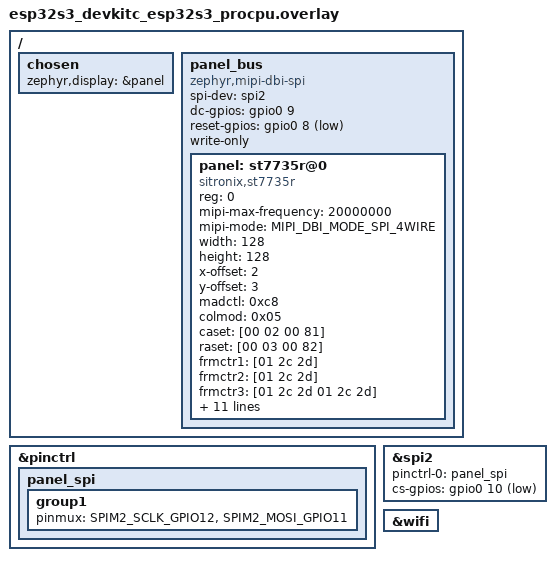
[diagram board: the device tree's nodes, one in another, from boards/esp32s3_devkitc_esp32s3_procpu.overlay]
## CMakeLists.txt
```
cmake_minimum_required(VERSION 3.20.0)
find_package(Zephyr REQUIRED HINTS $ENV{ZEPHYR_BASE})
project(lvgl_esp32s3)
target_include_directories(app PRIVATE include ui "${ZEPHYR_BASE}/../modules/lib/cjson")
target_sources(app PRIVATE src/main.c src/sensor_model.c src/sensor_json.c
  src/response_buffer.c ui/ui.c "${ZEPHYR_BASE}/../modules/lib/cjson/cJSON.c")
if(CONFIG_APP_NETWORK)
  target_sources(app PRIVATE src/config_store.c src/wifi_manager.c src/api_client.c src/provisioning.c)
  # Only a public CA certificate is embedded. Runtime credentials stay in NVS.
  if(APP_CA_CERT_FILE)
    file(READ "${APP_CA_CERT_FILE}" ca_hex HEX)
    string(REGEX REPLACE "(..)" "0x\\1," ca_bytes "${ca_hex}")
    file(WRITE "${PROJECT_BINARY_DIR}/api_ca.inc" "${ca_bytes}0x00")
  else()
    file(WRITE "${PROJECT_BINARY_DIR}/api_ca.inc" "0x00")
  endif()
  target_include_directories(app PRIVATE "${PROJECT_BINARY_DIR}")
endif()

target_compile_definitions(app PRIVATE CJSON_NESTING_LIMIT=16)
```

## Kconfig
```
mainmenu "128x128 Zephyr sensor display"
source "Kconfig.zephyr"
menu "Sensor application"
config APP_NETWORK
    bool "Wi-Fi, settings and HTTPS polling"
    default n
config APP_WIFI_RETRY_SECONDS
    int "Wi-Fi retry interval"
    range 1 300
    default 10
config APP_POLL_SECONDS
    int "HTTPS polling interval"
    range 1 3600
    default 10
endmenu
```

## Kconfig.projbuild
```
menu "Example Configuration"

    config ESP_WIFI_SSID
        string "WiFi SSID"
        default "İD"
        help
            SSID (network name) for the example to connect to.

    config ESP_WIFI_PASSWORD
        string "WiFi Password"
        default "Pasword*"
        help
            WiFi password (WPA or WPA2) for the example to use.

    config ESP_MAXIMUM_RETRY
        int "Maximum retry"
        default 5
        help
            Set the Maximum retry to avoid station reconnecting to the AP unlimited when the AP is really inexistent.

    choice ESP_WIFI_SCAN_AUTH_MODE_THRESHOLD
        prompt "WiFi Scan auth mode threshold"
        default ESP_WIFI_AUTH_WPA2_PSK
        help
            The weakest authmode to accept in the scan mode.
            This value defaults to ESP_WIFI_AUTH_WPA2_PSK incase password is present and ESP_WIFI_AUTH_OPEN is used.
            Please select ESP_WIFI_AUTH_WEP/ESP_WIFI_AUTH_WPA_PSK incase AP is operating in WEP/WPA mode.

        config ESP_WIFI_AUTH_OPEN
            bool "OPEN"
        config ESP_WIFI_AUTH_WEP
            bool "WEP"
        config ESP_WIFI_AUTH_WPA_PSK
            bool "WPA PSK"
        config ESP_WIFI_AUTH_WPA2_PSK
            bool "WPA2 PSK"
        config ESP_WIFI_AUTH_WPA_WPA2_PSK
            bool "WPA/WPA2 PSK"
        config ESP_WIFI_AUTH_WPA3_PSK
            bool "WPA3 PSK"
        config ESP_WIFI_AUTH_WPA2_WPA3_PSK
            bool "WPA2/WPA3 PSK"
        config ESP_WIFI_AUTH_WAPI_PSK
            bool "WAPI PSK"
    endchoice

endmenu
```

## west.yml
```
manifest:
  version: "0.13"
  projects:
    - name: zephyr
      url: https://github.com/zephyrproject-rtos/zephyr
      revision: v4.1.0
      import:
        name-allowlist: [cmsis, hal_espressif, mbedtls, lvgl]
    - name: cjson
      url: https://github.com/DaveGamble/cJSON
      revision: v1.7.18
      path: modules/lib/cjson
  self:
    path: LVGL-ESP32S3
```

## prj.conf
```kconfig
CONFIG_DISPLAY=y
CONFIG_LVGL=y
CONFIG_LV_COLOR_DEPTH_16=y
CONFIG_LV_USE_LABEL=y
CONFIG_LV_USE_BUTTON=y
CONFIG_LV_FONT_MONTSERRAT_14=y
CONFIG_LV_FONT_MONTSERRAT_24=y
CONFIG_LV_Z_MEM_POOL_SIZE=16384
CONFIG_MAIN_STACK_SIZE=4096
CONFIG_HEAP_MEM_POOL_SIZE=16384
CONFIG_LOG=y
CONFIG_LOG_DEFAULT_LEVEL=3
```

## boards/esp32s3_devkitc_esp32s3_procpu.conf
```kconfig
CONFIG_APP_NETWORK=y
CONFIG_SPI=y
CONFIG_GPIO=y
CONFIG_WIFI=y
CONFIG_WIFI_ESP32=y
CONFIG_NET_L2_ETHERNET=y
CONFIG_NETWORKING=y
CONFIG_NET_IPV4=y
CONFIG_NET_IPV6=n
CONFIG_NET_DHCPV4=y
CONFIG_NET_TCP=y
CONFIG_NET_UDP=y
CONFIG_NET_SOCKETS=y
CONFIG_NET_MGMT=y
CONFIG_NET_MGMT_EVENT=y
CONFIG_NET_MGMT_EVENT_INFO=y
CONFIG_DNS_RESOLVER=y
CONFIG_HTTP_CLIENT=y
CONFIG_SNTP=y
CONFIG_POSIX_TIMERS=y
CONFIG_NET_SOCKETS_SOCKOPT_TLS=y
CONFIG_TLS_CREDENTIALS=y
CONFIG_MBEDTLS=y
CONFIG_MBEDTLS_ENABLE_HEAP=y
CONFIG_MBEDTLS_HEAP_SIZE=49152
CONFIG_MBEDTLS_PEM_CERTIFICATE_FORMAT=y
CONFIG_MBEDTLS_SSL_MAX_CONTENT_LEN=4096
CONFIG_NEWLIB_LIBC=y
CONFIG_FLASH=y
CONFIG_FLASH_MAP=y
CONFIG_FLASH_PAGE_LAYOUT=y
CONFIG_NVS=y
CONFIG_SETTINGS=y
CONFIG_SETTINGS_NVS=y
CONFIG_SHELL=y
CONFIG_SHELL_STACK_SIZE=4096
CONFIG_SHELL_CMD_BUFF_SIZE=1536
CONFIG_REBOOT=y
CONFIG_HEAP_MEM_POOL_SIZE=49152
CONFIG_NET_PKT_RX_COUNT=16
CONFIG_NET_PKT_TX_COUNT=16
CONFIG_NET_BUF_RX_COUNT=32
CONFIG_NET_BUF_TX_COUNT=32
```

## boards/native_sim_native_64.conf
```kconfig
CONFIG_SDL_DISPLAY=y
CONFIG_INPUT=y
CONFIG_LV_Z_POINTER_INPUT=y
```

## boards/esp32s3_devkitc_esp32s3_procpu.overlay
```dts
/* Reference wiring only: ESP32-S3-DevKitC + 128x128 ST7735R.
 * Confirm the controller and wiring on your module before using this overlay.
 * SPI: SCK=12 MOSI=11 CS=10 DC=9 RESET=8. Backlight: external 3.3 V.
 */
#include <zephyr/dt-bindings/gpio/gpio.h>
#include <zephyr/dt-bindings/pinctrl/esp32s3-pinctrl.h>
/ {
    chosen {
        zephyr,display = &panel;
    };
    panel_bus {
        compatible = "zephyr,mipi-dbi-spi";
        spi-dev = <&spi2>;
        dc-gpios = <&gpio0 9 GPIO_ACTIVE_HIGH>;
        reset-gpios = <&gpio0 8 GPIO_ACTIVE_LOW>;
        write-only;
        #address-cells = <1>;
        #size-cells = <0>;
    panel: st7735r@0 {
        compatible = "sitronix,st7735r";
        reg = <0>;
        mipi-max-frequency = <20000000>;
        mipi-mode = "MIPI_DBI_MODE_SPI_4WIRE";
        width = <128>;
        height = <128>;
        x-offset = <2>;
        y-offset = <3>;
        madctl = <0xc8>;
        colmod = <0x05>;
        caset = [00 02 00 81];
        raset = [00 03 00 82];
        frmctr1 = [01 2c 2d];
        frmctr2 = [01 2c 2d];
        frmctr3 = [01 2c 2d 01 2c 2d];
        invctr = <0x07>;
        pwctr1 = [a2 02 84];
        pwctr2 = [c5];
        pwctr3 = [0a 00];
        pwctr4 = [8a 2a];
        pwctr5 = [8a ee];
        vmctr1 = <0x0e>;
        gamctrp1 = [02 1c 07 12 37 32 29 2d 29 25 2b 39 00 01 03 10];
        gamctrn1 = [03 1d 07 06 2e 2c 29 2d 2e 2e 37 3f 00 00 02 10];
    };
    };
};
&pinctrl {
    panel_spi: panel_spi {
        group1 {
            pinmux = <SPIM2_SCLK_GPIO12>, <SPIM2_MOSI_GPIO11>;
        };
    };
};
&spi2 {
    status = "okay";
    pinctrl-0 = <&panel_spi>;
    pinctrl-names = "default";
    cs-gpios = <&gpio0 10 GPIO_ACTIVE_LOW>;
};
&wifi {
    status = "okay";
};
```

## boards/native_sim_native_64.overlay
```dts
&sdl_dc {
    width = <128>;
    height = <128>;
};
```

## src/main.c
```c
#include "ui.h"
#include "sensor_model.h"
#include <zephyr/device.h>
#include <zephyr/drivers/display.h>
#include <zephyr/kernel.h>
#include <zephyr/logging/log.h>
#ifdef CONFIG_APP_NETWORK
#include "config_store.h"
#include "wifi_manager.h"
#include "api_client.h"
#endif
LOG_MODULE_REGISTER(panel_app);
int main(void)
{
    const struct device *display = DEVICE_DT_GET(DT_CHOSEN(zephyr_display));
    if (!device_is_ready(display)) {
        LOG_ERR("Display device is not ready");
        return 0;
    }
    struct display_capabilities caps;
    display_get_capabilities(display, &caps);
    if (caps.x_resolution != 128 || caps.y_resolution != 128) {
        LOG_ERR("This UI requires a 128x128 display");
        return 0;
    }
    ui_init();
    lv_timer_handler();
    display_blanking_off(display);
#ifdef CONFIG_APP_NETWORK
    static struct app_config config;
    int err = config_store_init();
    if (!err) {
        config_store_get(&config);
        if (config.ssid[0]) {
            err = wifi_manager_init(config.ssid, config.password);
            if (!err && config.api_host[0]) {
                err = api_client_start(&config);
            }
        } else {
            LOG_INF("Provision with 'panel set', then reboot");
        }
    }
    if (err) {
        sensor_model_error(err);
        LOG_ERR("Network initialization failed: %d", err);
    }
#endif
    /* Only this thread calls LVGL. Workers publish plain data under a mutex. */
    for (;;) {
        struct sensor_state state;
        sensor_model_get(&state);
        bool online = false;
#ifdef CONFIG_APP_NETWORK
        online = wifi_manager_is_connected();
#endif
        ui_render(&state, online);
        lv_timer_handler();
        k_sleep(K_MSEC(20));
    }
}
```

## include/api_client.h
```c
#ifndef API_CLIENT_H
#define API_CLIENT_H
#include "config_store.h"
int api_client_start(const struct app_config *config);
#endif
```

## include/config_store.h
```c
#ifndef PANEL_CONFIG_STORE_H
#define PANEL_CONFIG_STORE_H
struct app_config {
    char ssid[33];
    char password[65];
    char api_host[128];
    char api_path[192];
    char api_body[1024];
    char ntp_host[128];
};
int config_store_init(void);
void config_store_get(struct app_config *out);
int config_store_set(const char *key, const char *value);
#endif
```

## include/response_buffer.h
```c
#ifndef RESPONSE_BUFFER_H
#define RESPONSE_BUFFER_H
#include <stddef.h>
struct response_buffer {
    char data[4096];
    size_t used;
    int error;
};
int response_buffer_append(struct response_buffer *buffer, const char *data, size_t length);
#endif
```

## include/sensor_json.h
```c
#ifndef SENSOR_JSON_H
#define SENSOR_JSON_H
#include <stddef.h>
#include <stdint.h>
/* Length excludes the terminating NUL; input must have length + 1 bytes. */
int sensor_json_parse(const char *json, size_t length, int32_t *centi_value);
#endif
```

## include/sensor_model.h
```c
#ifndef SENSOR_MODEL_H
#define SENSOR_MODEL_H
#include <stdbool.h>
#include <stdint.h>
#include <zephyr/kernel.h>
struct sensor_state {
    bool valid;
    int32_t centi_value;
    int64_t updated_ms;
    int error;
};
void sensor_model_update(int32_t value);
void sensor_model_error(int error);
void sensor_model_get(struct sensor_state *out);
void sensor_request_refresh(void);
int sensor_wait_refresh(k_timeout_t timeout);
#endif
```

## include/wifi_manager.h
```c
#ifndef WIFI_MANAGER_H
#define WIFI_MANAGER_H
#include <stdbool.h>
#include <zephyr/kernel.h>

typedef enum {
    WIFI_MANAGER_DISCONNECTED,
    WIFI_MANAGER_CONNECTING,
    WIFI_MANAGER_CONNECTED
} wifi_manager_state_t;
/* Initialize once from main after settings have loaded. */
int wifi_manager_init(const char *ssid, const char *password);
bool wifi_manager_is_connected(void);
wifi_manager_state_t wifi_manager_get_state(void);
/* Single MQTT consumer; always rechecks current state after waking. */
int wifi_manager_wait_ready(k_timeout_t timeout);
#endif
```

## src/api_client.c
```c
#include "api_client.h"
#include "wifi_manager.h"
#include "sensor_model.h"
#include "sensor_json.h"
#include "response_buffer.h"
#include <errno.h>
#include <string.h>
#include <time.h>
#include <zephyr/kernel.h>
#include <zephyr/logging/log.h>
#include <zephyr/net/http/client.h>
#include <zephyr/net/socket.h>
#include <zephyr/net/sntp.h>
#include <zephyr/net/tls_credentials.h>
#include <zephyr/posix/time.h>
LOG_MODULE_REGISTER(api_client);
static struct app_config config;
static const unsigned char ca_certificate[] = {
#include "api_ca.inc"
};
static const sec_tag_t ca_tag = 1;
static struct k_thread api_thread;
K_THREAD_STACK_DEFINE(panel_api_stack, 8192);
static uint8_t receive_buffer[1024];
static struct response_buffer response;
static bool complete;
static int http_status;

static void receive_response(struct http_response *rsp,
                             enum http_final_call final, void *user_data)
{
    ARG_UNUSED(user_data);
    http_status = rsp->http_status_code;
    response_buffer_append(&response, rsp->body_frag_start, rsp->body_frag_len);
    if (final == HTTP_DATA_FINAL) {
        complete = true;
    }
}

static int synchronize_time(void)
{
    struct sntp_time time;
    int err = sntp_simple(config.ntp_host, 10000, &time);
    if (err) {
        return err;
    }
    struct timespec now = { .tv_sec = time.seconds, .tv_nsec = 0 };
    return clock_settime(CLOCK_REALTIME, &now) ? -errno : 0;
}

static int request_sample(void)
{
    struct zsock_addrinfo *addresses = NULL;
    struct zsock_addrinfo hints = {
        .ai_family = AF_INET, .ai_socktype = SOCK_STREAM
    };
    if (zsock_getaddrinfo(config.api_host, "443", &hints, &addresses)) {
        return -EHOSTUNREACH;
    }
    int socket = zsock_socket(AF_INET, SOCK_STREAM, IPPROTO_TLS_1_2);
    int err = 0;
    if (socket < 0) {
        err = -errno;
        goto free_addresses;
    }
    int verify = TLS_PEER_VERIFY_REQUIRED;
    struct timeval timeout = { .tv_sec = 10 };
    if (zsock_setsockopt(socket, SOL_TLS, TLS_SEC_TAG_LIST, &ca_tag, sizeof(ca_tag)) ||
        zsock_setsockopt(socket, SOL_TLS, TLS_HOSTNAME, config.api_host,
                         strlen(config.api_host)) ||
        zsock_setsockopt(socket, SOL_TLS, TLS_PEER_VERIFY, &verify, sizeof(verify)) ||
        zsock_setsockopt(socket, SOL_SOCKET, SO_RCVTIMEO, &timeout, sizeof(timeout)) ||
        zsock_setsockopt(socket, SOL_SOCKET, SO_SNDTIMEO, &timeout, sizeof(timeout))) {
        err = -errno;
        goto close_socket;
    }
    if (!addresses || zsock_connect(socket, addresses->ai_addr, addresses->ai_addrlen)) {
        err = addresses ? -errno : -EHOSTUNREACH;
        goto close_socket;
    }
    response = (struct response_buffer){0};
    complete = false;
    http_status = 0;
    struct http_request request = {
        .method = HTTP_POST,
        .url = config.api_path,
        .host = config.api_host,
        .protocol = "HTTP/1.1",
        .content_type_value = "application/json",
        .payload = config.api_body,
        .payload_len = strlen(config.api_body),
        .response = receive_response,
        .recv_buf = receive_buffer,
        .recv_buf_len = sizeof(receive_buffer),
    };
    err = http_client_req(socket, &request, 10000, NULL);
    if (err >= 0) {
        err = response.error ? response.error :
              !complete ? -EBADMSG :
              http_status != 200 ? -EACCES : 0;
        if (!err) {
            int32_t value;
            err = sensor_json_parse(response.data, response.used, &value);
            if (!err) {
                sensor_model_update(value);
            }
        }
    }
close_socket:
    zsock_close(socket);
free_addresses:
    if (addresses) {
        zsock_freeaddrinfo(addresses);
    }
    return err;
}

static void poll_api(void *a, void *b, void *c)
{
    ARG_UNUSED(a); ARG_UNUSED(b); ARG_UNUSED(c);
    bool time_ready = false;
    for (;;) {
        if (wifi_manager_wait_ready(K_SECONDS(5))) {
            continue;
        }
        int err = 0;
        if (!time_ready) {
            err = synchronize_time();
            time_ready = !err;
        }
        if (!err) {
            err = request_sample();
        }
        if (err) {
            sensor_model_error(err);
            LOG_WRN("Sensor request failed: %d", err);
        }
        sensor_wait_refresh(K_SECONDS(CONFIG_APP_POLL_SECONDS));
    }
}

int api_client_start(const struct app_config *cfg)
{
    if (!cfg || !cfg->api_host[0] || cfg->api_path[0] != '/') {
        return -EINVAL;
    }
    /* No verification bypass: an absent CA keeps HTTPS disabled. */
    if (sizeof(ca_certificate) <= 1) {
        return -EACCES;
    }
    int err = tls_credential_add(ca_tag, TLS_CREDENTIAL_CA_CERTIFICATE,
                                 ca_certificate, sizeof(ca_certificate));
    if (err) {
        return err;
    }
    config = *cfg;
    k_thread_create(&api_thread, panel_api_stack, K_THREAD_STACK_SIZEOF(panel_api_stack),
                    poll_api, NULL, NULL, NULL, 7, 0, K_NO_WAIT);
    return 0;
}
```

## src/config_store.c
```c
#include "config_store.h"
#include <errno.h>
#include <string.h>
#include <stdio.h>
#include <zephyr/kernel.h>
#include <zephyr/settings/settings.h>
#include <zephyr/sys/util.h>

static struct app_config config = { .api_path = "/", .api_body = "{}", .ntp_host = "pool.ntp.org" };
K_MUTEX_DEFINE(config_lock);

static char *field(const char *key, size_t *size)
{
    if (!key) {
        return NULL;
    }
    if (!strcmp(key, "ssid")) {
        *size = sizeof(config.ssid);
        return config.ssid;
    }
    if (!strcmp(key, "password")) {
        *size = sizeof(config.password);
        return config.password;
    }
    if (!strcmp(key, "api_host")) {
        *size = sizeof(config.api_host);
        return config.api_host;
    }
    if (!strcmp(key, "api_path")) {
        *size = sizeof(config.api_path);
        return config.api_path;
    }
    if (!strcmp(key, "api_body")) {
        *size = sizeof(config.api_body);
        return config.api_body;
    }
    if (!strcmp(key, "ntp_host")) {
        *size = sizeof(config.ntp_host);
        return config.ntp_host;
    }
    return NULL;
}

static int load_setting(const char *key, size_t len,
                        settings_read_cb read_cb, void *cb_arg)
{
    char value[1024] = {0};
    size_t capacity;
    char *dst = field(key, &capacity);
    if (!dst) {
        return -ENOENT;
    }
    if (len >= capacity) {
        return -EINVAL;
    }
    ssize_t read = read_cb(cb_arg, value, len);
    if (read < 0) {
        return (int)read;
    }
    if ((size_t)read != len || memchr(value, '\0', len)) {
        return -EINVAL;
    }
    k_mutex_lock(&config_lock, K_FOREVER);
    memset(dst, 0, capacity);
    memcpy(dst, value, len);
    k_mutex_unlock(&config_lock);
    return 0;
}
SETTINGS_STATIC_HANDLER_DEFINE(iot, "iot", NULL, load_setting, NULL, NULL);

int config_store_init(void)
{
    int err = settings_subsys_init();
    return err ? err : settings_load_subtree("iot");
}

void config_store_get(struct app_config *out)
{
    k_mutex_lock(&config_lock, K_FOREVER);
    *out = config;
    k_mutex_unlock(&config_lock);
}

int config_store_set(const char *key, const char *value)
{
    size_t capacity;
    char path[48];
    char *dst = field(key, &capacity);
    if (!dst || !value) {
        return -EINVAL;
    }
    size_t len = strlen(value);
    if (len >= capacity || (!strcmp(key, "api_path") && (!len || value[0] != '/'))) {
        return -EINVAL;
    }
    if (!strcmp(key, "password") && len && (len < 8 || len > 63)) {
        return -EINVAL;
    }
    if ((!strcmp(key, "api_host") || !strcmp(key, "ntp_host")) &&
        strpbrk(value, "\r\n/ :")) {
        return -EINVAL;
    }
    if (!strcmp(key, "api_path") && strpbrk(value, "\r\n")) {
        return -EINVAL;
    }
    /* Serialize flash and RAM updates so concurrent writers cannot diverge. */
    k_mutex_lock(&config_lock, K_FOREVER);
    snprintf(path, sizeof(path), "iot/%s", key);
    int err = settings_save_one(path, value, len);
    if (!err) {
        memset(dst, 0, capacity);
        memcpy(dst, value, len);
    }
    k_mutex_unlock(&config_lock);
    return err;
}
```

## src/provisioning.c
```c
#include "config_store.h"
#include "sensor_model.h"
#include <zephyr/shell/shell.h>
#include <zephyr/sys/reboot.h>
static int set_config(const struct shell *sh, size_t argc, char **argv)
{
    ARG_UNUSED(argc);
    int err = config_store_set(argv[1], argv[2]);
    if (err) {
        shell_error(sh, "Setting rejected: %d", err);
    } else {
        shell_print(sh, "Saved. Reboot to apply.");
    }
    return err;
}
static int refresh(const struct shell *sh, size_t argc, char **argv)
{
    ARG_UNUSED(sh); ARG_UNUSED(argc); ARG_UNUSED(argv);
    sensor_request_refresh();
    return 0;
}
static int reboot_device(const struct shell *sh, size_t argc, char **argv)
{
    ARG_UNUSED(sh); ARG_UNUSED(argc); ARG_UNUSED(argv);
    sys_reboot(SYS_REBOOT_COLD);
    return 0;
}
SHELL_STATIC_SUBCMD_SET_CREATE(panel_commands,
    SHELL_CMD_ARG(set, NULL, "set <ssid|password|api_host|api_path|api_body|ntp_host> <value>",
                  set_config, 3, 0),
    SHELL_CMD_ARG(refresh, NULL, "Request a fresh sample", refresh, 1, 0),
    SHELL_CMD_ARG(reboot, NULL, "Reboot to apply settings", reboot_device, 1, 0),
    SHELL_SUBCMD_SET_END
);
SHELL_CMD_REGISTER(panel, &panel_commands, "Panel provisioning", NULL);
```

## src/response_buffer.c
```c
#include "response_buffer.h"
#include <errno.h>
#include <string.h>
int response_buffer_append(struct response_buffer *buffer, const char *data, size_t length)
{
    if (buffer->error) {
        return buffer->error;
    }
    if ((!data && length) || length > sizeof(buffer->data) - 1 - buffer->used) {
        buffer->error = -EMSGSIZE;
        return buffer->error;
    }
    if (length) {
        memcpy(buffer->data + buffer->used, data, length);
    }
    buffer->used += length;
    buffer->data[buffer->used] = 0;
    return 0;
}
```

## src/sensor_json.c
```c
#include "sensor_json.h"
#include <errno.h>
#include <stdbool.h>
#include <math.h>
#include <string.h>
#include <cJSON.h>

int sensor_json_parse(const char *json, size_t length, int32_t *centi_value)
{
    if (!json || !centi_value || !length || length > 4095 ||
        json[length] != '\0' || memchr(json, '\0', length)) {
        return -EINVAL;
    }
    cJSON *root = cJSON_ParseWithLengthOpts(json, length + 1, NULL, true);
    if (!root) {
        return -EBADMSG;
    }
    const cJSON *things = cJSON_GetObjectItemCaseSensitive(root, "things");
    const cJSON *thing = cJSON_GetArrayItem(things, 0);
    const cJSON *device = cJSON_GetObjectItemCaseSensitive(thing, "device");
    const cJSON *values = cJSON_GetObjectItemCaseSensitive(device, "SensorValue");
    const cJSON *sample = cJSON_GetArrayItem(values, 0);
    const cJSON *value = cJSON_GetObjectItemCaseSensitive(sample, "value");
    int err = -EBADMSG;
    if (cJSON_IsArray(things) && cJSON_IsArray(values) && cJSON_IsNumber(value) &&
        isfinite(value->valuedouble) && fabs(value->valuedouble) <= 100000.0) {
        double scaled = value->valuedouble * 100.0;
        *centi_value = (int32_t)(scaled + (scaled < 0 ? -0.5 : 0.5));
        err = 0;
    }
    cJSON_Delete(root);
    return err;
}
```

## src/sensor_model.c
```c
#include "sensor_model.h"
#include <zephyr/kernel.h>
static struct sensor_state state;
K_MUTEX_DEFINE(sensor_lock);
K_SEM_DEFINE(refresh_signal, 0, 1);
void sensor_model_update(int32_t value)
{
    k_mutex_lock(&sensor_lock, K_FOREVER);
    state = (struct sensor_state) {
        .valid = true, .centi_value = value, .updated_ms = k_uptime_get()
    };
    k_mutex_unlock(&sensor_lock);
}
void sensor_model_error(int error)
{
    k_mutex_lock(&sensor_lock, K_FOREVER);
    state.error = error;
    k_mutex_unlock(&sensor_lock);
}
void sensor_model_get(struct sensor_state *out)
{
    k_mutex_lock(&sensor_lock, K_FOREVER);
    *out = state;
    k_mutex_unlock(&sensor_lock);
}
void sensor_request_refresh(void)
{
    k_sem_give(&refresh_signal);
}
int sensor_wait_refresh(k_timeout_t timeout)
{
    return k_sem_take(&refresh_signal, timeout);
}
```
